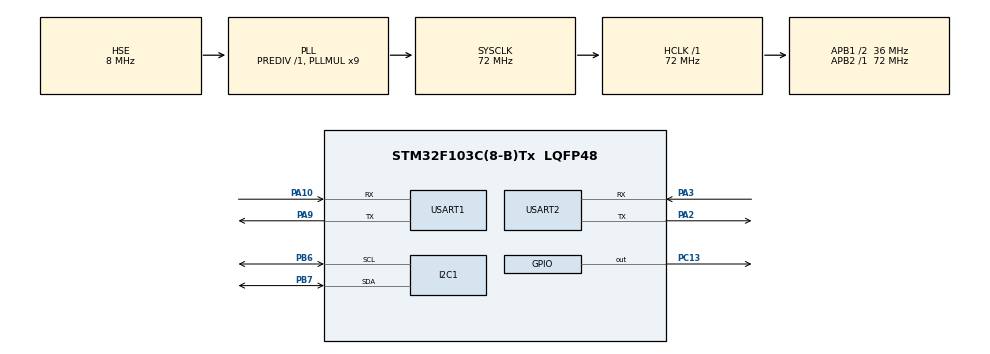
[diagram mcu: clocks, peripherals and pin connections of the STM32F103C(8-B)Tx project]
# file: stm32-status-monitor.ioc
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Dma.Request0=USART1_RX
Dma.USART1_RX.0.Direction=DMA_PERIPH_TO_MEMORY
Dma.USART1_RX.0.Instance=DMA1_Channel5
Dma.USART1_RX.0.MemDataAlignment=DMA_MDATAALIGN_BYTE
Dma.USART1_RX.0.MemInc=DMA_MINC_ENABLE
Dma.USART1_RX.0.Mode=DMA_CIRCULAR
Dma.USART1_RX.0.PeriphDataAlignment=DMA_PDATAALIGN_BYTE
Dma.USART1_RX.0.PeriphInc=DMA_PINC_DISABLE
Dma.USART1_RX.0.Priority=DMA_PRIORITY_MEDIUM
FREERTOS.BinarySemaphores01=status_message_pending,Dynamic,NULL
FREERTOS.Queues01=status_message_queue,16,Status,0,Dynamic,NULL,NULL
FREERTOS.Tasks01=display,24,128,Start_display,Default,NULL,Dynamic,NULL,NULL;status_message_,32,128,Start_status_message_parser,Default,NULL,Dynamic,NULL,NULL
Mcu.Family=STM32F1
Mcu.Name=STM32F103C(8-B)Tx
Mcu.Package=LQFP48
NVIC.DMA1_Channel5_IRQn=true\:5\:0\:false\:false\:true\:true\:false\:true
NVIC.PriorityGroup=NVIC_PRIORITYGROUP_4
NVIC.TIM3_IRQn=true\:0\:0\:false\:false\:true\:false\:false\:true
NVIC.TimeBase=TIM3_IRQn
NVIC.TimeBaseIP=TIM3
NVIC.USART1_IRQn=true\:5\:0\:false\:false\:true\:true\:true\:true
PA10.Mode=Asynchronous
PA10.Signal=USART1_RX
PA13.Mode=Serial_Wire
PA13.Signal=SYS_JTMS-SWDIO
PA14.Mode=Serial_Wire
PA14.Signal=SYS_JTCK-SWCLK
PA2.Mode=Asynchronous
PA2.Signal=USART2_TX
PA3.Mode=Asynchronous
PA3.Signal=USART2_RX
PA9.Mode=Asynchronous
PA9.Signal=USART1_TX
PB6.Mode=I2C
PB6.Signal=I2C1_SCL
PB7.Mode=I2C
PB7.Signal=I2C1_SDA
PC13-TAMPER-RTC.GPIO_ModeDefaultOutputPP=GPIO_MODE_OUTPUT_OD
PC13-TAMPER-RTC.GPIO_PuPd=GPIO_NOPULL
PC13-TAMPER-RTC.GPIO_Speed=GPIO_SPEED_FREQ_LOW
PC13-TAMPER-RTC.PinState=GPIO_PIN_SET
PC13-TAMPER-RTC.Signal=GPIO_Output
PD0-OSC_IN.Mode=HSE-External-Oscillator
PD0-OSC_IN.Signal=RCC_OSC_IN
PD1-OSC_OUT.Mode=HSE-External-Oscillator
PD1-OSC_OUT.Signal=RCC_OSC_OUT
ProjectManager.HeapSize=0x200
ProjectManager.StackSize=0x400
ProjectManager.TargetToolchain=STM32CubeIDE
RCC.AHBFreq_Value=72000000
RCC.APB1CLKDivider=RCC_HCLK_DIV2
RCC.APB1Freq_Value=36000000
RCC.APB1TimFreq_Value=72000000
RCC.APB2Freq_Value=72000000
RCC.APB2TimFreq_Value=72000000
RCC.HCLKFreq_Value=72000000
RCC.PLLMUL=RCC_PLL_MUL9
RCC.PLLSourceVirtual=RCC_PLLSOURCE_HSE
RCC.SYSCLKFreq_VALUE=72000000
RCC.SYSCLKSource=RCC_SYSCLKSOURCE_PLLCLK
RCC.USBFreq_Value=72000000
USART1.VirtualMode=VM_ASYNC
USART2.VirtualMode=VM_ASYNC
VP_FREERTOS_VS_CMSIS_V2.Mode=CMSIS_V2
VP_SYS_VS_tim3.Mode=TIM3
board=custom

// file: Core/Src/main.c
/* USER CODE BEGIN Header */
/**
  ******************************************************************************
  * @file           : main.c
  * @brief          : Main program body
  ******************************************************************************
  * @attention
  *
  * <h2><center>&copy; Copyright (c) 2021 STMicroelectronics.
  * All rights reserved.</center></h2>
  *
  * This software component is licensed by ST under BSD 3-Clause license,
  * the "License"; You may not use this file except in compliance with the
  * License. You may obtain a copy of the License at:
  *                        opensource.org/licenses/BSD-3-Clause
  *
  ******************************************************************************
  */
/* USER CODE END Header */
#include "main.h"
#include "cmsis_os.h"

/* USER CODE BEGIN Includes */
#include <stdio.h>
#include "display.h"
#include "status_message_parser.h"
#include "status.pb.h"

/* USER CODE END Includes */

I2C_HandleTypeDef hi2c1;

UART_HandleTypeDef huart1;
UART_HandleTypeDef huart2;
DMA_HandleTypeDef hdma_usart1_rx;

/* Definitions for display */
osThreadId_t displayHandle;
const osThreadAttr_t display_attributes = {
  .name = "display",
  .priority = (osPriority_t) osPriorityNormal,
  .stack_size = 128 * 4
};
/* Definitions for status_message_ */
osThreadId_t status_message_Handle;
const osThreadAttr_t status_message__attributes = {
  .name = "status_message_",
  .priority = (osPriority_t) osPriorityAboveNormal,
  .stack_size = 128 * 4
};
/* Definitions for status_message_queue */
osMessageQueueId_t status_message_queueHandle;
const osMessageQueueAttr_t status_message_queue_attributes = {
  .name = "status_message_queue"
};
/* Definitions for status_message_pending */
osSemaphoreId_t status_message_pendingHandle;
const osSemaphoreAttr_t status_message_pending_attributes = {
  .name = "status_message_pending"
};

void SystemClock_Config(void);
static void MX_GPIO_Init(void);
static void MX_DMA_Init(void);
static void MX_USART1_UART_Init(void);
static void MX_I2C1_Init(void);
static void MX_USART2_UART_Init(void);
void Start_display(void *argument);
void Start_status_message_parser(void *argument);

int main(void)
{

  /* MCU Configuration--------------------------------------------------------*/

  /* Reset of all peripherals, Initializes the Flash interface and the Systick. */
  HAL_Init();

  /* Configure the system clock */
  SystemClock_Config();

  /* Initialize all configured peripherals */
  MX_GPIO_Init();
  MX_DMA_Init();
  MX_USART1_UART_Init();
  MX_I2C1_Init();
  MX_USART2_UART_Init();
  /* USER CODE BEGIN 2 */
  HAL_GPIO_WritePin(GPIOC, GPIO_PIN_13, GPIO_PIN_RESET);
  /* USER CODE END 2 */

  /* Init scheduler */
  osKernelInitialize();

  /* Create the semaphores(s) */
  /* creation of status_message_pending */
  status_message_pendingHandle = osSemaphoreNew(1, 1, &status_message_pending_attributes);

  /* Create the queue(s) */
  /* creation of status_message_queue */
  status_message_queueHandle = osMessageQueueNew (16, sizeof(Status), &status_message_queue_attributes);

  /* Create the thread(s) */
  /* creation of display */
  displayHandle = osThreadNew(Start_display, NULL, &display_attributes);

  /* creation of status_message_ */
  status_message_Handle = osThreadNew(Start_status_message_parser, NULL, &status_message__attributes);

  /* Start scheduler */
  osKernelStart();

  /* We should never get here as control is now taken by the scheduler */
  /* Infinite loop */
  while (1)
  {

  }
}

void SystemClock_Config(void)
{
  RCC_OscInitTypeDef RCC_OscInitStruct = {0};
  RCC_ClkInitTypeDef RCC_ClkInitStruct = {0};

  /** Initializes the RCC Oscillators according to the specified parameters
  * in the RCC_OscInitTypeDef structure.
  */
  RCC_OscInitStruct.OscillatorType = RCC_OSCILLATORTYPE_HSE;
  RCC_OscInitStruct.HSEState = RCC_HSE_ON;
  RCC_OscInitStruct.HSEPredivValue = RCC_HSE_PREDIV_DIV1;
  RCC_OscInitStruct.HSIState = RCC_HSI_ON;
  RCC_OscInitStruct.PLL.PLLState = RCC_PLL_ON;
  RCC_OscInitStruct.PLL.PLLSource = RCC_PLLSOURCE_HSE;
  RCC_OscInitStruct.PLL.PLLMUL = RCC_PLL_MUL9;
  if (HAL_RCC_OscConfig(&RCC_OscInitStruct) != HAL_OK)
  {
    Error_Handler();
  }
  /** Initializes the CPU, AHB and APB buses clocks
  */
  RCC_ClkInitStruct.ClockType = RCC_CLOCKTYPE_HCLK|RCC_CLOCKTYPE_SYSCLK
                              |RCC_CLOCKTYPE_PCLK1|RCC_CLOCKTYPE_PCLK2;
  RCC_ClkInitStruct.SYSCLKSource = RCC_SYSCLKSOURCE_PLLCLK;
  RCC_ClkInitStruct.AHBCLKDivider = RCC_SYSCLK_DIV1;
  RCC_ClkInitStruct.APB1CLKDivider = RCC_HCLK_DIV2;
  RCC_ClkInitStruct.APB2CLKDivider = RCC_HCLK_DIV1;

  if (HAL_RCC_ClockConfig(&RCC_ClkInitStruct, FLASH_LATENCY_2) != HAL_OK)
  {
    Error_Handler();
  }
}

static void MX_I2C1_Init(void)
{

  hi2c1.Instance = I2C1;
  hi2c1.Init.ClockSpeed = 100000;
  hi2c1.Init.DutyCycle = I2C_DUTYCYCLE_2;
  hi2c1.Init.OwnAddress1 = 0;
  hi2c1.Init.AddressingMode = I2C_ADDRESSINGMODE_7BIT;
  hi2c1.Init.DualAddressMode = I2C_DUALADDRESS_DISABLE;
  hi2c1.Init.OwnAddress2 = 0;
  hi2c1.Init.GeneralCallMode = I2C_GENERALCALL_DISABLE;
  hi2c1.Init.NoStretchMode = I2C_NOSTRETCH_DISABLE;
  if (HAL_I2C_Init(&hi2c1) != HAL_OK)
  {
    Error_Handler();
  }

}

static void MX_USART1_UART_Init(void)
{

  huart1.Instance = USART1;
  huart1.Init.BaudRate = 115200;
  huart1.Init.WordLength = UART_WORDLENGTH_8B;
  huart1.Init.StopBits = UART_STOPBITS_1;
  huart1.Init.Parity = UART_PARITY_NONE;
  huart1.Init.Mode = UART_MODE_TX_RX;
  huart1.Init.HwFlowCtl = UART_HWCONTROL_NONE;
  huart1.Init.OverSampling = UART_OVERSAMPLING_16;
  if (HAL_UART_Init(&huart1) != HAL_OK)
  {
    Error_Handler();
  }
  /* USER CODE BEGIN USART1_Init 2 */

	__HAL_UART_ENABLE_IT(&huart1, UART_IT_IDLE);
  /* USER CODE END USART1_Init 2 */

}

static void MX_USART2_UART_Init(void)
{

  huart2.Instance = USART2;
  huart2.Init.BaudRate = 115200;
  huart2.Init.WordLength = UART_WORDLENGTH_8B;
  huart2.Init.StopBits = UART_STOPBITS_1;
  huart2.Init.Parity = UART_PARITY_NONE;
  huart2.Init.Mode = UART_MODE_TX_RX;
  huart2.Init.HwFlowCtl = UART_HWCONTROL_NONE;
  huart2.Init.OverSampling = UART_OVERSAMPLING_16;
  if (HAL_UART_Init(&huart2) != HAL_OK)
  {
    Error_Handler();
  }

}

static void MX_DMA_Init(void)
{

  /* DMA controller clock enable */
  __HAL_RCC_DMA1_CLK_ENABLE();

  /* DMA interrupt init */
  /* DMA1_Channel5_IRQn interrupt configuration */
  HAL_NVIC_SetPriority(DMA1_Channel5_IRQn, 5, 0);
  HAL_NVIC_EnableIRQ(DMA1_Channel5_IRQn);

}

static void MX_GPIO_Init(void)
{
  GPIO_InitTypeDef GPIO_InitStruct = {0};

  /* GPIO Ports Clock Enable */
  __HAL_RCC_GPIOC_CLK_ENABLE();
  __HAL_RCC_GPIOD_CLK_ENABLE();
  __HAL_RCC_GPIOA_CLK_ENABLE();
  __HAL_RCC_GPIOB_CLK_ENABLE();

  /*Configure GPIO pin Output Level */
  HAL_GPIO_WritePin(GPIOC, GPIO_PIN_13, GPIO_PIN_SET);

  /*Configure GPIO pin : PC13 */
  GPIO_InitStruct.Pin = GPIO_PIN_13;
  GPIO_InitStruct.Mode = GPIO_MODE_OUTPUT_OD;
  GPIO_InitStruct.Pull = GPIO_NOPULL;
  GPIO_InitStruct.Speed = GPIO_SPEED_FREQ_LOW;
  HAL_GPIO_Init(GPIOC, &GPIO_InitStruct);

}

void Start_display(void *argument)
{
  /* USER CODE BEGIN 5 */
  display__main();
  /* USER CODE END 5 */
}

void Start_status_message_parser(void *argument)
{
  /* USER CODE BEGIN Start_status_message_parser */
  status_message_parser__main();
  /* USER CODE END Start_status_message_parser */
}

 /**
  * @brief  Period elapsed callback in non blocking mode
  * @note   This function is called  when TIM3 interrupt took place, inside
  * HAL_TIM_IRQHandler(). It makes a direct call to HAL_IncTick() to increment
  * a global variable "uwTick" used as application time base.
  * @param  htim : TIM handle
  * @retval None
  */
void HAL_TIM_PeriodElapsedCallback(TIM_HandleTypeDef *htim)
{
  if (htim->Instance == TIM3) {
    HAL_IncTick();
  }
}

void Error_Handler(void)
{
  /* USER CODE BEGIN Error_Handler_Debug */
  /* User can add his own implementation to report the HAL error return state */
  __disable_irq();

  HAL_GPIO_WritePin(GPIOC, GPIO_PIN_13, GPIO_PIN_SET);

  while (1)
  {
  }
  /* USER CODE END Error_Handler_Debug */
}

/************************ (C) COPYRIGHT STMicroelectronics *****END OF FILE****/
